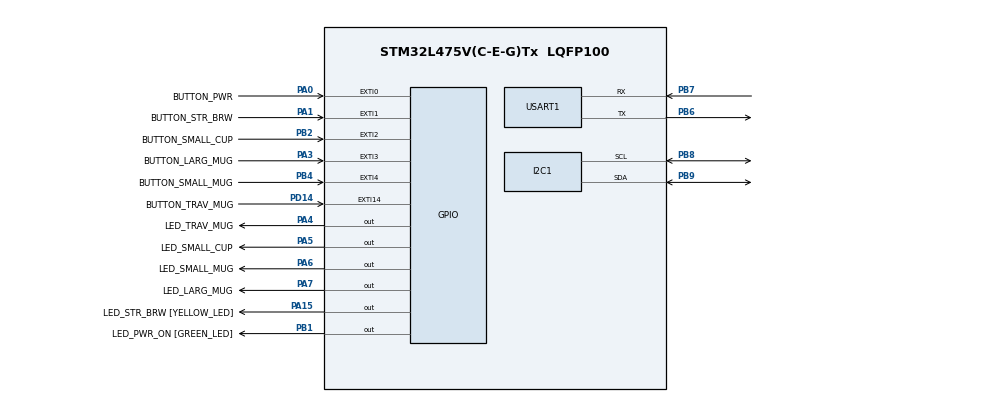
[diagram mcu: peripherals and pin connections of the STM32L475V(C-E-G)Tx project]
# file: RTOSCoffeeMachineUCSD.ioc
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FREERTOS.BinarySemaphores01=powerOnSem,Dynamic,NULL;strongBrewSem,Dynamic,NULL
FREERTOS.Mutexes01=brewingMutex,Dynamic,NULL
FREERTOS.Tasks01=defaultTask,1,128,StartDefaultTask,Default,NULL,Dynamic,NULL,NULL;myTask02,0,128,powerOnTask,Default,NULL,Dynamic,NULL,NULL;myTask03,-1,128,strongBrewTask,Default,NULL,Dynamic,NULL,NULL;myTask04,-1,128,brewTravelMug,Default,NULL,Dynamic,NULL,NULL;myTask05,-1,128,brewLargeMug,Default,NULL,Dynamic,NULL,NULL;myTask06,-1,128,brewSmallMug,Default,NULL,Dynamic,NULL,NULL;myTask07,-1,128,brewSmallCup,Default,NULL,Dynamic,NULL,NULL
FREERTOS.Timers01=autoOffTimer,pvAutoOffTimerOneShot,osTimerOnce,Default,NULL,Dynamic,NULL
FREERTOS.configTOTAL_HEAP_SIZE=6000
FREERTOS.configUSE_TIMERS=1
Mcu.Family=STM32L4
Mcu.Name=STM32L475V(C-E-G)Tx
Mcu.Package=LQFP100
NVIC.EXTI0_IRQn=true\:5\:0\:false\:false\:true\:true\:true\:true\:true
NVIC.EXTI15_10_IRQn=true\:5\:0\:false\:false\:true\:true\:true\:true\:true
NVIC.EXTI1_IRQn=true\:5\:0\:false\:false\:true\:true\:true\:true\:true
NVIC.EXTI2_IRQn=true\:5\:0\:false\:false\:true\:true\:true\:true\:true
NVIC.EXTI3_IRQn=true\:5\:0\:false\:false\:true\:true\:true\:true\:true
NVIC.EXTI4_IRQn=true\:5\:0\:false\:false\:true\:true\:true\:true\:true
NVIC.PriorityGroup=NVIC_PRIORITYGROUP_4
NVIC.TIM1_UP_TIM16_IRQn=true\:15\:0\:false\:false\:true\:false\:false\:true\:true
NVIC.TimeBase=TIM1_UP_TIM16_IRQn
NVIC.TimeBaseIP=TIM1
NVIC.USART1_IRQn=true\:5\:0\:false\:false\:true\:true\:true\:true\:true
PA0.GPIO_Label=BUTTON_PWR
PA0.Signal=GPXTI0
PA1.GPIO_Label=BUTTON_STR_BRW
PA1.Signal=GPXTI1
PA15\ (JTDI).GPIO_Label=LED_STR_BRW [YELLOW_LED]
PA15\ (JTDI).Signal=GPIO_Output
PA3.GPIO_Label=BUTTON_LARG_MUG
PA3.Signal=GPXTI3
PA4.GPIO_Label=LED_TRAV_MUG
PA4.Signal=GPIO_Output
PA5.GPIO_Label=LED_SMALL_CUP
PA5.Signal=GPIO_Output
PA6.GPIO_Label=LED_SMALL_MUG
PA6.Signal=GPIO_Output
PA7.GPIO_Label=LED_LARG_MUG
PA7.Signal=GPIO_Output
PB1.GPIO_Label=LED_PWR_ON [GREEN_LED]
PB1.Signal=GPIO_Output
PB10.Signal=I2C2_SCL
PB11.Signal=I2C2_SDA
PB2.GPIO_Label=BUTTON_SMALL_CUP
PB2.Signal=GPXTI2
PB4\ (NJTRST).GPIO_Label=BUTTON_SMALL_MUG
PB4\ (NJTRST).Signal=GPXTI4
PB6.Mode=Asynchronous
PB6.Signal=USART1_TX
PB7.Mode=Asynchronous
PB7.Signal=USART1_RX
PB8.Mode=I2C
PB8.Signal=I2C1_SCL
PB9.Mode=I2C
PB9.Signal=I2C1_SDA
PD14.GPIO_Label=BUTTON_TRAV_MUG
PD14.Signal=GPXTI14
ProjectManager.HeapSize=0x200
ProjectManager.StackSize=0x400
ProjectManager.TargetToolchain=STM32CubeIDE
RCC.ADCFreq_Value=32000000
RCC.HSE_VALUE=8000000
RCC.HSI_VALUE=16000000
RCC.LSE_VALUE=32768
RCC.MSI_VALUE=4000000
RCC.PLLSAI1N=16
RCC.USBFreq_Value=32000000
RCC.VCOOutputFreq_Value=32000000
USART1.VirtualMode-Asynchronous=VM_ASYNC
VP_FREERTOS_VS_CMSIS_V1.Mode=CMSIS_V1
VP_SYS_VS_tim1.Mode=TIM1
board=custom

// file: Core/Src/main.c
/* USER CODE BEGIN Header */
/**
  ******************************************************************************
  * @file           : main.c
  * @brief          : Main program body, meant for system/peripheral init & RTOS setup
  ******************************************************************************
  * @attention
  *
  * Copyright (c) 2024 STMicroelectronics.
  * All rights reserved.
  *
  * This software is licensed under terms that can be found in the LICENSE file
  * in the root directory of this software component.
  * If no LICENSE file comes with this software, it is provided AS-IS.
  *
  ******************************************************************************
  */
/* USER CODE END Header */
#include "main.h"
#include "cmsis_os.h"

/* USER CODE BEGIN Includes */
#include <string.h>
#include <stdio.h>
#include <stdbool.h>
#include "peripherals.h"
#include "utils.h"
#include "typedefs.h"
#include "globals.h"
#include "comm_handler.h"
#include "tasks.h"

/* USER CODE END Includes */

I2C_HandleTypeDef hi2c1;
UART_HandleTypeDef huart1;
osThreadId StartDefaultTaskHandle;
osThreadId powerOnTaskHandle;
osThreadId strongBrewTaskHandle;
osThreadId brewerTaskHandle;
osTimerId autoOffTimerHandle;
osMutexId brewingMutexHandle;
osSemaphoreId powerOnSemHandle;
osSemaphoreId strongBrewSemHandle;
/* USER CODE BEGIN PV */
EventGroupHandle_t xEventGroup;			// Event Group Handle
/* USER CODE END PV */

void SystemClock_Config(void);

int main(void)
{
  /* USER CODE BEGIN 1 */
	// Event Group Creation
	xEventGroup = xEventGroupCreate();
  /* USER CODE END 1 */

  /* MCU Configuration--------------------------------------------------------*/

  /* Reset of all peripherals, Initializes the Flash interface and the Systick. */
  HAL_Init();

  /* Configure the system clock */
  SystemClock_Config();

  /* Initialize all configured peripherals */
  MX_GPIO_Init();
  MX_USART1_UART_Init();
  MX_I2C1_Init();

  /* Create the mutex(es) */
  /* definition and creation of brewingMutex */
  osMutexDef(brewingMutex);
  brewingMutexHandle = osMutexCreate(osMutex(brewingMutex));

  /* Create the semaphores(s) */
  /* definition and creation of powerOnSem */
  osSemaphoreDef(powerOnSem);
  powerOnSemHandle = osSemaphoreCreate(osSemaphore(powerOnSem), 1);

  /* definition and creation of strongBrewSem */
  osSemaphoreDef(strongBrewSem);
  strongBrewSemHandle = osSemaphoreCreate(osSemaphore(strongBrewSem), 1);

  /* USER CODE BEGIN RTOS_SEMAPHORES */

  // Initialize semaphores count to 0
  if (powerOnSemHandle != NULL && strongBrewSemHandle != NULL)
  {
      osSemaphoreWait(powerOnSemHandle, 0);
      osSemaphoreWait(strongBrewSemHandle, 0);
  }
  /* add semaphores, ... */
  /* USER CODE END RTOS_SEMAPHORES */

  /* Create the timer(s) */
  /* definition and creation of autoOffTimer */
  osTimerDef(autoOffTimer, pvAutoOffTimerOneShot);
  autoOffTimerHandle = osTimerCreate(osTimer(autoOffTimer), osTimerOnce, NULL);

  /* Create the thread(s) */
  /* definition and creation of StartDefaultTask */
  osThreadDef(StartDefaultTask, StartDefaultTask, osPriorityAboveNormal, 0, 128);
  StartDefaultTaskHandle = osThreadCreate(osThread(StartDefaultTask), NULL);

  /* definition and creation of powerOnTask */
  osThreadDef(powerOnTask, powerOnTask, osPriorityNormal, 0, 128);
  powerOnTaskHandle = osThreadCreate(osThread(powerOnTask), NULL);

  /* definition and creation of strongBrewTask */
  osThreadDef(strongBrewTask, strongBrewTask, osPriorityBelowNormal, 0, 128);
  strongBrewTaskHandle = osThreadCreate(osThread(strongBrewTask), NULL);

  /* definition and creation of brewTravelMug */
  osThreadDef(brewerTask, brewerTask, osPriorityBelowNormal, 0, 128);
  brewerTaskHandle = osThreadCreate(osThread(brewerTask), NULL);
  /* USER CODE BEGIN RTOS_THREADS */
  /* add threads, ... */

  /* Add the communication task */
  //osThreadDef(commHandlerTask, commHandlerTask, osPriorityNormal, 0, 128);
  //osThreadCreate(osThread(commHandlerTask), NULL);
  /* USER CODE END RTOS_THREADS */

  /* Start scheduler */
  osKernelStart();

  /* We should never get here as control is now taken by the scheduler */
  /* Infinite loop */
  while (1)
  {
  }
}

void SystemClock_Config(void)
{
  RCC_OscInitTypeDef RCC_OscInitStruct = {0};
  RCC_ClkInitTypeDef RCC_ClkInitStruct = {0};

  /** Configure the main internal regulator output voltage
  */
  if (HAL_PWREx_ControlVoltageScaling(PWR_REGULATOR_VOLTAGE_SCALE1) != HAL_OK)
  {
    Error_Handler();
  }

  /** Initializes the RCC Oscillators according to the specified parameters
  * in the RCC_OscInitTypeDef structure.
  */
  RCC_OscInitStruct.OscillatorType = RCC_OSCILLATORTYPE_MSI;
  RCC_OscInitStruct.MSIState = RCC_MSI_ON;
  RCC_OscInitStruct.MSICalibrationValue = 0;
  RCC_OscInitStruct.MSIClockRange = RCC_MSIRANGE_6;
  RCC_OscInitStruct.PLL.PLLState = RCC_PLL_NONE;
  if (HAL_RCC_OscConfig(&RCC_OscInitStruct) != HAL_OK)
  {
    Error_Handler();
  }

  /** Initializes the CPU, AHB and APB buses clocks
  */
  RCC_ClkInitStruct.ClockType = RCC_CLOCKTYPE_HCLK|RCC_CLOCKTYPE_SYSCLK
                              |RCC_CLOCKTYPE_PCLK1|RCC_CLOCKTYPE_PCLK2;
  RCC_ClkInitStruct.SYSCLKSource = RCC_SYSCLKSOURCE_MSI;
  RCC_ClkInitStruct.AHBCLKDivider = RCC_SYSCLK_DIV1;
  RCC_ClkInitStruct.APB1CLKDivider = RCC_HCLK_DIV1;
  RCC_ClkInitStruct.APB2CLKDivider = RCC_HCLK_DIV1;

  if (HAL_RCC_ClockConfig(&RCC_ClkInitStruct, FLASH_LATENCY_0) != HAL_OK)
  {
    Error_Handler();
  }
}

void HAL_TIM_PeriodElapsedCallback(TIM_HandleTypeDef *htim)
{
  if (htim->Instance == TIM1) {
    HAL_IncTick();
  }
}

void Error_Handler(void)
{
  __disable_irq();
  while (1)
  {
  }
}
